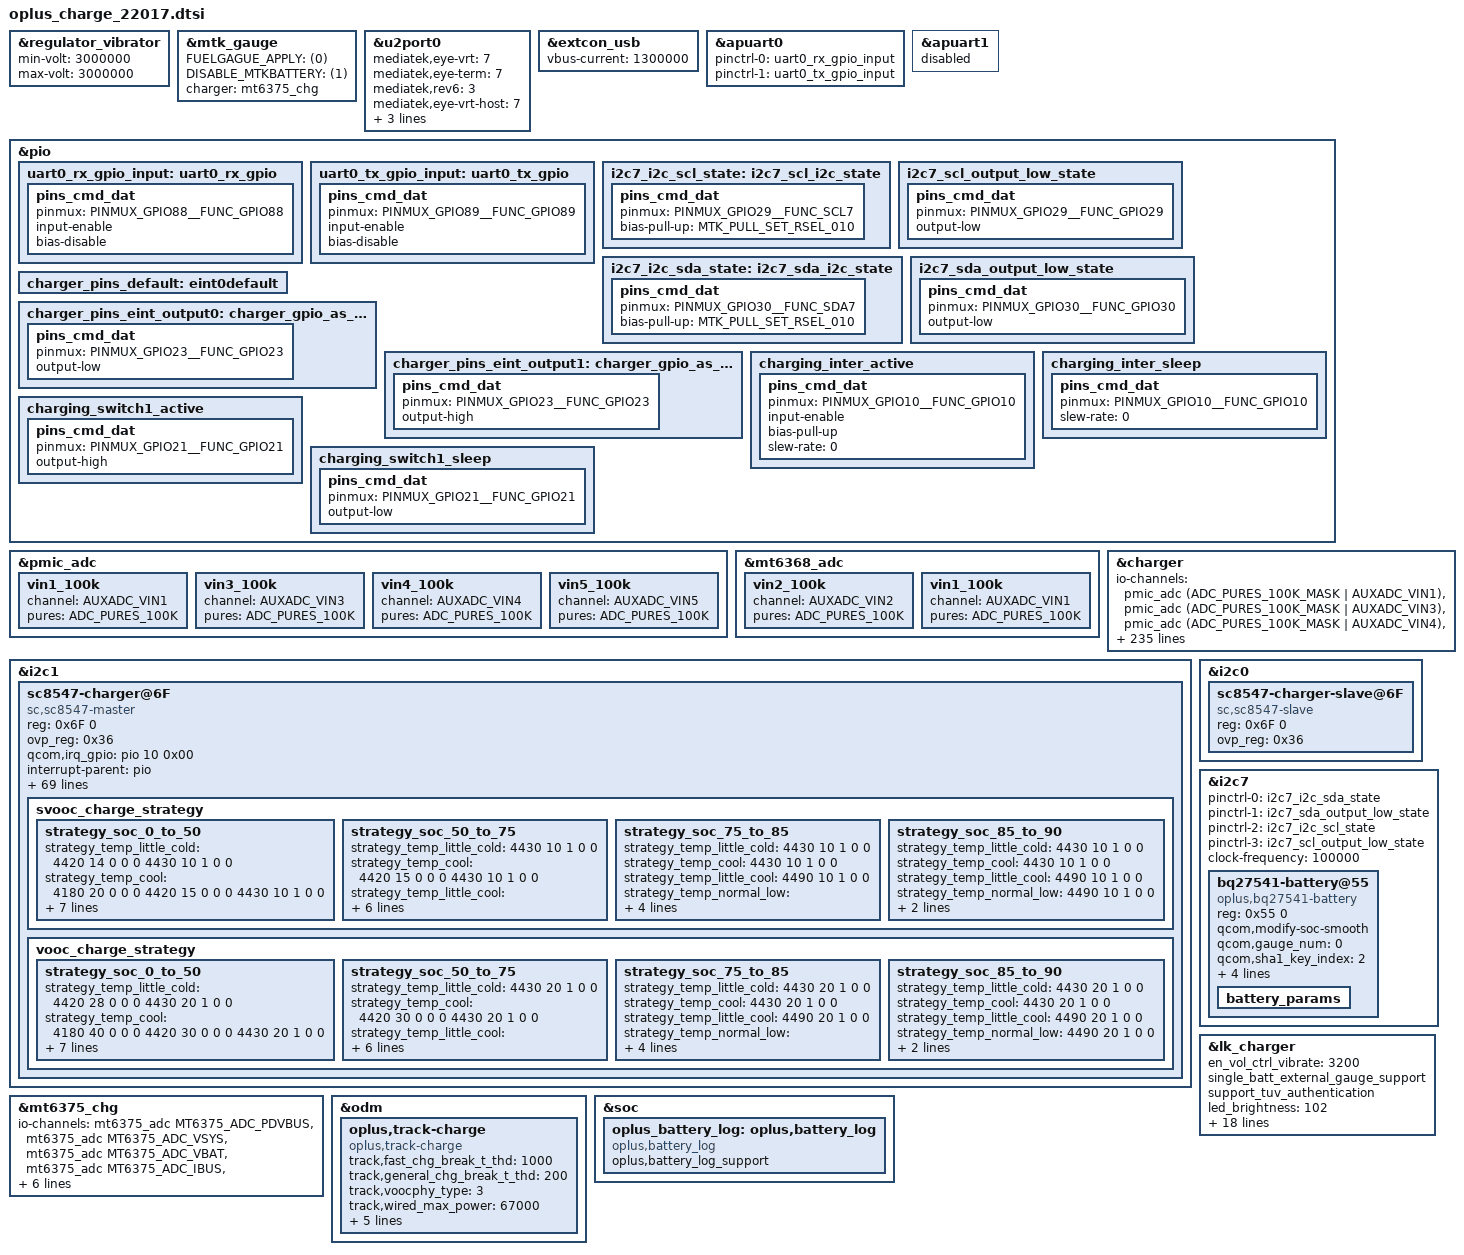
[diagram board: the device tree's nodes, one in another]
// SPDX-License-Identifier: GPL-2.0-only
/*
* Copyright (C) 2021-2020 Oplus. All rights reserved.
*/
#include <dt-bindings/iio/mt635x-auxadc.h>
#include <dt-bindings/pinctrl/mt6373-pinfunc.h>
#include <dt-bindings/pinctrl/mt65xx.h>
#include "oplus_chg.h"
#include <dt-bindings/iio/adc/mediatek,mt6375_adc.h>

&regulator_vibrator{
	min-volt = <3000000>;
	max-volt = <3000000>;
};

&mtk_gauge {
	FUELGAGUE_APPLY = <(0)>;
	DISABLE_MTKBATTERY = <(1)>;
	charger = <&mt6375_chg>;
};

&u2port0 {
	mediatek,eye-vrt = <7>;
	mediatek,eye-term = <7>;
	mediatek,rev6 = <3>;
	mediatek,eye-vrt-host = <7>;
	mediatek,eye-term-host = <7>;
	mediatek,rev6-host = <3>;
	mediatek,discth = <0xd>;
};

&extcon_usb {
	vbus-current = <1300000>;
};

&apuart0 {
	pinctrl-names = "uart0_rx_gpio", "uart0_tx_gpio";
	pinctrl-0 = <&uart0_rx_gpio_input>;
	pinctrl-1 = <&uart0_tx_gpio_input>;
	status = "okay";
};

&apuart1 {
	status = "disabled";
};

&pio {
	uart0_rx_gpio_input: uart0_rx_gpio {
		pins_cmd_dat {
			pinmux = <PINMUX_GPIO88__FUNC_GPIO88>;
			input-enable;
			bias-disable;
		};
	};

	uart0_tx_gpio_input: uart0_tx_gpio {
		pins_cmd_dat {
			pinmux = <PINMUX_GPIO89__FUNC_GPIO89>;
			input-enable;
			bias-disable;
		};
	};
};

&pmic_adc {
	vin1_100k {
		channel = <AUXADC_VIN1>;
		pures = <ADC_PURES_100K>;
	};
	vin3_100k {
		channel = <AUXADC_VIN3>;
		pures = <ADC_PURES_100K>;
	};
	vin4_100k {
		channel = <AUXADC_VIN4>;
		pures = <ADC_PURES_100K>;
	};
	vin5_100k {
		channel = <AUXADC_VIN5>;
		pures = <ADC_PURES_100K>;
	};
};

&mt6368_adc {
	vin2_100k {
		channel = <AUXADC_VIN2>;
		pures = <ADC_PURES_100K>;
	};
	vin1_100k {
		channel = <AUXADC_VIN1>;
		pures = <ADC_PURES_100K>;
	};
};

&charger {

	io-channels = <&pmic_adc (ADC_PURES_100K_MASK | AUXADC_VIN1)>,
			<&pmic_adc (ADC_PURES_100K_MASK | AUXADC_VIN3)>,
			<&pmic_adc (ADC_PURES_100K_MASK | AUXADC_VIN4)>,
			<&mt6368_adc AUXADC_VIN2>,
			<&mt6368_adc AUXADC_VIN1>,
			<&pmic_adc (ADC_PURES_100K_MASK | AUXADC_VIN5)>;
	io-channel-names = "auxadc2_ntc_sub_bat_tem",
			"usb_temp_v_l",
			"usb_temp_v_r",
			"auxadc5_batt_btb_temp",
			"auxadc6_usb_btb_temp",
			"auxadc5-chargeric_temp";

	pinctrl-names = "default",
			"charger_gpio_as_output_low",  /*Level 1 switch*/
			"charger_gpio_as_output_high";

	pinctrl-0 = <&charger_pins_default>;
	pinctrl-1 = <&charger_pins_eint_output0>;
	pinctrl-2 = <&charger_pins_eint_output1>;

	//for oplus chg framework:
	qcom,pd_input_current_charger_ma = <1500>;
	qcom,qc_input_current_charger_ma = <1500>;
	qcom,input_current_charger_ma = <2200>;
	qcom,input_current_usb_ma = <500>;
	qcom,input_current_cdp_ma = <1500>;
	qcom,input_current_camera_ma = <1200>;
	qcom,input_current_calling_ma = <1500>;

	qcom,led_warm_bat_decidegc = <350>;
	qcom,led_high_bat_decidegc = <370>;
	qcom,input_current_led_ma = <1200>;
	qcom,input_current_led_ma_high = <1200>;
	qcom,input_current_led_ma_warm = <1500>;
	qcom,input_current_led_ma_normal = <2000>;
	qcom,input_current_led_ma_forcmcc = <500>;
	qcom,input_current_led_ma_limit_high = <1200>;

	qcom,vooc_temp_bat_normal_decidegc = <350>;
	qcom,vooc_temp_bat_warm_decidegc = <370>;
	qcom,vooc_temp_bat_hot_decidegc = <440>;
	qcom,input_current_vooc_led_ma_high = <1200>;
	qcom,input_current_vooc_led_ma_warm = <1800>;
	qcom,input_current_vooc_led_ma_normal = <3600>;
	qcom,input_current_vooc_ma_normal = <3600>;
	qcom,input_current_vooc_ma_warm = <3200>;
	qcom,input_current_vooc_ma_high = <2200>;

	qcom,overtemp_bat_decidegc = <350>;
	qcom,iterm_disabled = <0>;
	//sw_full_count = <25>;
	qcom,iterm_ma = <255>;
	qcom,recharge-mv = <100>;

	qcom,batt_capacity_mah = <4500>; /*typical capacity*/
	//qcom,batt_capacity_mah = <4390>; /*rated capacity*/
	qcom,usb_high_than_bat_decidegc = <168>;

	qcom,removed_bat_decidegc = <390>;  /* < -39C */

	qcom,cold_bat_decidegc = <100>;  /* -10C ~ 0C */
	qcom,temp_cold_vfloat_mv = <4435>;
	qcom,temp_freeze_fastchg_current_ma_high = <1100>;
	qcom,temp_freeze_fastchg_current_ma_low = <1100>;
	qcom,temp_freeze_fastchg_current_ma = <1100>;
	qcom,temp_cold_fastchg_current_ma = <1100>;

	qcom,little_cold_bat_decidegc = <0>;    /* 0C ~ 5C */
	qcom,temp_little_cold_vfloat_mv = <4435>;
	qcom,temp_little_cold_fastchg_current_ma_high = <2200>;
	qcom,temp_little_cold_fastchg_current_ma_low = <2200>;
	qcom,temp_little_cold_fastchg_current_ma = <2200>;
	qcom,qc_temp_little_cold_fastchg_current_ma_high = <2594>;
	qcom,qc_temp_little_cold_fastchg_current_ma_low = <2700>;
	qcom,pd_temp_little_cold_fastchg_current_ma_high = <2594>;
	qcom,pd_temp_little_cold_fastchg_current_ma_low = <2700>;

	qcom,cool_bat_decidegc = <50>;  /* 5C ~ 12C */
	qcom,temp_cool_vfloat_mv = <4435>;
	qcom,temp_cool_fastchg_current_ma_high = <2200>;
	qcom,temp_cool_fastchg_current_ma_low = <2200>;
	qcom,qc_temp_cool_fastchg_current_ma_high = <2700>;
	qcom,qc_temp_cool_fastchg_current_ma_low = <2700>;
	qcom,pd_temp_cool_fastchg_current_ma_high = <2700>;
	qcom,pd_temp_cool_fastchg_current_ma_low = <2700>;

	qcom,little_cool_bat_decidegc = <120>;  /* 12C ~ 16C */
	qcom,temp_little_cool_vfloat_mv = <4435>;
	qcom,temp_little_cool_fastchg_current_ma = <2200>;
	qcom,pd_temp_little_cool_fastchg_current_ma = <2700>;
	qcom,qc_temp_little_cool_fastchg_current_ma = <2700>;

	qcom,normal_bat_decidegc = <160>;       /* 16C ~ 45C */
	qcom,temp_normal_vfloat_mv = <4435>;
	qcom,temp_normal_fastchg_current_ma = <2200>;
	qcom,pd_temp_normal_fastchg_current_ma = <2700>;
	qcom,qc_temp_normal_fastchg_current_ma = <2700>;

	qcom,warm_bat_decidegc = <450>;         /* 45C ~ 53C */ /*8pin Bat Vooc project need add 3 degree C*/
	qcom,temp_warm_vfloat_mv = <4130>;
	qcom,temp_warm_fastchg_current_ma = <1152>;
	qcom,pd_temp_warm_fastchg_current_ma = <1152>;
	qcom,qc_temp_warm_fastchg_current_ma = <1152>;
	qcom,temp_warm_fastchg_current_ma_led_on = <500>;

	qcom,hot_bat_decidegc = <530>;  /* > 53C */

	qcom,non_standard_vfloat_mv = <3980>;
	qcom,non_standard_fastchg_current_ma = <512>;

	qcom,short_c_bat_cv_mv = <4330>;
	qcom,short_c_bat_vfloat_mv = <3800>;
	qcom,short_c_bat_fastchg_current_ma = <512>;
	qcom,short_c_bat_vfloat_sw_limit = <3750>;

	qcom,cold_vfloat_sw_limit = <4385>;
	qcom,little_cold_vfloat_sw_limit = <4385>;
	qcom,cool_vfloat_sw_limit = <4385>;
	qcom,little_cool_vfloat_sw_limit = <4385>;
	qcom,normal_vfloat_sw_limit = <4385>;
	qcom,warm_vfloat_sw_limit = <4080>;
	qcom,non_standard_vfloat_sw_limit = <3930>;

	qcom,max_chg_time_sec = <64000>;
	qcom,charger_hv_thr = <10000>;
	qcom,charger_recv_thr = <9800>;
	qcom,charger_lv_thr = <3400>;
	qcom,vbatt_full_thr = <4435>;
	qcom,vbatt_hv_thr = <4600>;

	qcom,vfloat_step_mv = <16>;
	qcom,non_standard_vfloat_over_sw_limit = <3990>;
	qcom,cold_vfloat_over_sw_limit = <4445>;
	qcom,little_cold_vfloat_over_sw_limit = <4445>;
	qcom,cool_vfloat_over_sw_limit = <4445>;
	qcom,little_cool_vfloat_over_sw_limit = <4445>;
	qcom,normal_vfloat_over_sw_limit = <4445>;
	qcom,warm_vfloat_over_sw_limit = <4140>;

	qcom,usbtemp_batt_temp_low = <50>;
	qcom,usbtemp_batt_temp_high = <50>;
	qcom,usbtemp_ntc_temp_low = <57>;
	qcom,usbtemp_ntc_temp_high = <69>;
	qcom,usbtemp_temp_gap_low_with_batt_temp = <7>;
	qcom,usbtemp_temp_gap_high_with_batt_temp = <12>;
	qcom,usbtemp_temp_gap_low_without_batt_temp = <12>;
	qcom,usbtemp_temp_gap_high_without_batt_temp = <24>;
	qcom.usbtemp_rise_fast_temp_low = <3>;
	qcom.usbtemp_rise_fast_temp_high = <3>;
	qcom.usbtemp_rise_fast_temp_count_low = <30>;
	qcom.usbtemp_rise_fast_temp_count_high = <20>;

	qcom,usbtemp_cool_down_ntc_low = <54>;
	qcom,usbtemp_cool_down_ntc_high = <65>;
	qcom,usbtemp_cool_down_gap_low = <12>;
	qcom,usbtemp_cool_down_gap_high = <20>;
	qcom,usbtemp_cool_down_recover_ntc_low = <48>;
	qcom,usbtemp_cool_down_recover_ntc_high = <60>;
	qcom,usbtemp_cool_down_recover_gap_low = <6>;
	qcom,usbtemp_cool_down_recover_gap_high = <15>;

	qcom,vbatt_power_off = <3300>;
	qcom,vbatt_soc_1 = <3410>;
	qcom,vooc_project = <13>;
	qcom,vbatt_num = <1>;
	qcom,new_ui_warning_support;
	qcom,smart_charging_screenoff;
	qcom,smart_charge_version = <1>;

	qcom,normal_vterm_hw_inc = <18>;
	qcom,non_normal_vterm_hw_inc = <18>;
	qcom,usbtemp_batttemp_gap = <12>;

	qcom,ff1_normal_fastchg_ma = <1550>;
	qcom,ff1_warm_fastchg_ma = <1700>;	/* 35C ~ 40c */
	qcom,ff1_exit_step_ma = <100>;
	qcom,ff1_warm_exit_step_ma = <100>;
	qcom,ffc2_normal_fastchg_ma = <1550>;   /*12C~35c*/
	qcom,ffc2_warm_fastchg_ma = <1700>;	/* 35C ~ 40c */
	qcom,ffc2_temp_warm_decidegc = <350>;
	qcom,ffc2_temp_high_decidegc = <400>;
	qcom,ffc2_temp_low_decidegc = <120>;
	qcom,ffc2_exit_step_ma = <100>;
	qcom,ffc2_warm_exit_step_ma = <100>;

	qcom,ffc_normal_vfloat_sw_limit = <4485>;
	qcom,ffc2_normal_vfloat_sw_limit = <4485>;
	qcom,ffc_temp_normal_vfloat_mv = <4550>;
	qcom,ffc_normal_vfloat_over_sw_limit = <4550>;

	qcom,default_iterm_ma = <255>;
	qcom,default_temp_normal_fastchg_current_ma = <2200>;
	qcom,default_normal_vfloat_sw_limit = <4385>;
	qcom,default_temp_normal_vfloat_mv = <4435>;
	qcom,default_normal_vfloat_over_sw_limit = <4445>;

	qcom,default_temp_little_cool_fastchg_current_ma = <2200>;
	qcom,default_little_cool_vfloat_sw_limit = <4385>;
	qcom,default_temp_little_cool_vfloat_mv = <4435>;
	qcom,default_little_cool_vfloat_over_sw_limit = <4445>;

	oplus,poweroff_high_batt_temp = <720>;
	oplus,poweroff_emergency_batt_temp = <770>;
	oplus,usbtemp_batt_temp_over_hot = <60>;
	oplus,usbtemp_temp_gap_with_batt_temp_in_over_hot = <15>;

	//for PD9V or QC9V
	qcom,vbatt_pdqc_to_5v_thr = <4435>;
	qcom,vbatt_pdqc_to_9v_thr = <4435>;

	//for control:
	//qcom,suspend_after_full;
	//for smart charge begin
	qcom,smart_chg_bcc_support;
	//for smart charge end
	qcom,smart_chg_soh_support;
	qcom,check_batt_full_by_sw;
	qcom,chg_ctrl_by_lcd;
	qcom,chg_ctrl_by_camera;
	qcom,chg_ctrl_by_calling;
	qcom,sw_vfloat_over_protect_enable;
	qcom,usbtemp_dischg_by_pmic;
	qcom,support_usbtemp_protect_v2;
	qcom,support_abnormal_adapter;
	qcom,ffc_support;
	qcom,chargerid_vol_disable;
	qcom,support_ntc_01c_precision;
	qcom,voocphy_support = <3>;
	qcom,external_authenticate;
	qcom,chargerid_support;
	qcom,support_subboard_ntc;
	qcom,external_gauge;
	qcom,batt_num = <1>;
	qcom,vooc_show_ui_soc_decimal;
	qcom,ui_soc_decimal_speedmin = <20>;//2A
	qcom,ccdetect_by_wd0;
	oplus,boot_reset_adapter;
	//GPIO config:
	qcom,chargerid_switch-gpio = <&pio 23 0x00>;

	qcom,vooc-max-input-volt-support = <11000>;     //10V
	qcom,vooc-max-input-current-support = <3000>;   //6.5A

	oplus,switch2-ctrl-gpio = <&pio 21 0x00>;
	oplus,uart_tx-gpio = <&pio 89 0x00>;
	oplus,uart_rx-gpio = <&pio 88 0x00>;
};

/*#ifdef OPLUS_FEATURE_CHG_BASIC*/
&charger {
	//oplus,pps_ops = "cp-sc8571";
	qcom,pps_support_type = <0>;
	qcom,pps_warm_allow_vol = <4000>;
	qcom,pps_warm_allow_soc = <50>;
	qcom,pps_strategy_normal_current = <8000>;//6A
	qcom,pps_over_high_or_low_current = <8000>;
	qcom,pps_full_cool_sw_vbat = <4430>;
	qcom,pps_full_normal_sw_vbat = <4490>;
	qcom,pps_full_normal_hw_vbat = <4500>;
	qcom,pps_full_ffc_vbat = <4420>;
	qcom,pps_warm_full_voltage = <4130>;
	qcom,pps_full_cool_sw_vbat_30w = <4430>;
	qcom,pps_full_normal_sw_vbat_30w = <4430>;
	qcom,pps_full_normal_hw_vbat_30w = <4440>;
	oplus,pps_r_default = <120 10 10 15 15 15 15>;
	oplus,pps_rmos_mohm = <4>;
	oplus,pps_r_limit = <280 200 140 90 50>;
	oplus,pps_strategy_batt_high_temp = <425 430 435 400 415 420>;
	oplus,pps_strategy_high_current = <8000 8000 8000 8000 8000 8000>;
	oplus,pps_charge_strategy_soc = <0 15 35 55 75 85 95>;
	oplus,pps_charge_strategy_temp = <0 50 120 200 350 440 510>;
	oplus,pps_low_curr_full_strategy_temp = <120 200 350 440>;
};
/*endif OPLUS_FEATURE_CHG_BASIC*/

&i2c1 {
	status = "okay";
	sc8547-charger@6F{
		status = "okay";
		compatible = "sc,sc8547-master";
		reg = <0x6F 0>;
                ovp_reg = <0x36>; /* vbat_ovp:4.85V */

		qcom,irq_gpio = <&pio 10 0x00>;
		interrupt-parent = <&pio>;
		interrupts = <9 0>;

		pinctrl-names = "switch1_act_switch2_act", "switch1_sleep_switch2_sleep",
					"charging_inter_active", "charging_inter_sleep";
		pinctrl-0 = <&charging_switch1_active>; 
		pinctrl-1 = <&charging_switch1_sleep>;
		pinctrl-2 = <&charging_inter_active>;
		pinctrl-3 = <&charging_inter_sleep>;

		qcom,external_gauge_support;
		qcom,charging_switch1-gpio = <&pio 21 0x00>;

		qcom,voocphy_dual_cp_support;
		qcom,copycat_vooc_support;
		qcom,slave_cp_enable_thr = <1400>;		//2000-100mA
		qcom,slave_cp_disable_thr_high = <1100>;	//1500+100mA
		qcom,voocphy_current_default = <61>;

		qcom,svooc_cool_down_current_limit = <122 20 20 24 30 34 40 44 50 54 60 64 70 74>;
		qcom,vooc_cool_down_current_limit = <61 20 20 24 30 34 40 44 50 54 60 64 70 74>;

		qcom,vooc_multistep_initial_batt_temp = <1000>;
		qcom,vooc_little_cool_temp = <160>;
		qcom,vooc_cool_temp = <120>;
		qcom,vooc_little_cold_temp = <50>;
		qcom,vooc_normal_low_temp = <350>;
		qcom,vooc_strategy_normal_current = <122>;
		qcom,vooc_normal_to_little_cool_current = <100>;
		qcom,vooc_batt_over_high_temp = <510>;
		qcom,vooc-low-temp = <0>;

		qcom,vooc-high-temp = <500>;
		qcom,vooc-low-soc = <0>;
		qcom,vooc-high-soc = <90>;
		qcom,vooc-normal-high-temp = <430>;
		qcom,vooc-warm-allow-vol = <4000>;
		qcom,vooc-warm-allow-soc = <50>;

		qcom,vooc_strategy1_batt_high_temp0 = <385>;
		qcom,vooc_strategy1_batt_high_temp1 = <395>;
		qcom,vooc_strategy1_batt_high_temp2 = <420>;
		qcom,vooc_strategy1_batt_low_temp2 = <410>;
		qcom,vooc_strategy1_batt_low_temp1 = <385>;
		qcom,vooc_strategy1_batt_low_temp0 = <375>;

		qcom,vooc_strategy1_high_current0 = <80>;
		qcom,vooc_strategy1_high_current1 = <60>;
		qcom,vooc_strategy1_high_current2 = <40>;
		qcom,vooc_strategy1_low_current2 = <60>;
		qcom,vooc_strategy1_low_current1 = <80>;
		qcom,vooc_strategy1_low_current0 = <122>;

		qcom,voocphy_freq_mincore = <968000>;
		qcom,voocphy_freq_midcore = <1418000>;
		qcom,voocphy_freq_maxcore = <1418000>;
		qcom,voocphy_current_change_timeout = <100>;

		qcom,voocphy_ibat_over_current = <13500>;
		qcom,voocphy_svooc_cp_max_ibus = <3500>;
		qcom,voocphy_vooc_cp_max_ibus = <3500>;
		qcom,voocphy_cp_max_ibus = <3500>;

		qcom,abnormal_adapter_current = <122 50 50 50 40 40 30 30 20 20>;

		qcom,vooc_little_cold_full_voltage = <4430>;
		qcom,vooc_cool_full_voltage = <4430>;
		qcom,vooc_warm_full_voltage = <4130>;
		qcom,vooc_1time_full_voltage = <4490>;
		qcom,vooc_ntime_full_voltage = <4490>;
		qcom,low_curr_full_t1 = <120>;
		qcom,low_curr_full_t2 = <350>;
		qcom,low_curr_full_t3 = <430>;
		qcom,range1_low_curr_full = <1500 4490
						1400 4485
						1300 4470
						1200 4460
						1100 4450>;
		qcom,range2_low_curr_full = <1600 4490
						1400 4485
						1300 4470
						1200 4460
						1100 4450>;

		svooc_batt_sys_curve = <0 1 0 1 0 0 0	// 4000mA
					1 1 1 1 0 0 0	// 4604mV
					0 0 1 1 0 1 0	// 2600mA
					1 1 1 1 0 0 0	// 4604mV
					0 0 0 1 0 1 1	// 1100mA
					1 1 1 1 0 0 0>;	// 4604mV

		vooc_batt_sys_curve =  <0 1 0 1 0 0 0	// 4000mA
					1 1 1 1 0 0 0	// 4604mV
					0 0 1 1 0 1 0	// 2600mA
					1 1 1 1 0 0 0	// 4604mV
					0 0 0 1 0 1 1	// 1100mA
					1 1 1 1 0 0 0>;	// 4604mV

		svooc_charge_strategy {
			strategy_soc_0_to_50 {
				strategy_temp_little_cold =	<4420 14 0 0 0
								 4430 10 1 0 0>;
				strategy_temp_cool =	<4180 20 0 0 0
								 4420 15 0 0 0
								 4430 10 1 0 0>;
				strategy_temp_little_cool =	<4180 40 0 0 0
								 4350 30 0 0 0
								 4350 25 0 0 0
								 4480 20 0 0 0
								 4480 15 0 0 0
								 4490 10 1 0 0>;
				strategy_temp_normal_low =	<4200 61 0 60 0 //min*60*1000/500
								 4200 50 0 600 0 //min*60*1000/500
								 4350 40 0 0 0 //min*60*1000/500
								 4450 30 0 0 0
								 4450 25 0 0 0
								 4480 20 0 0 0
								 4480 15 0 0 0
								 4490 10 1 0 0>;
				strategy_temp_normal_high =	<4200 50 0 600 0 //min*60*1000/500
								 4350 40 0 1200 0 //min*60*1000/500
								 4450 30 0 0 0
								 4450 25 0 0 0
								 4480 20 0 0 0
								 4480 15 0 0 0
								 4490 10 1 0 0>;
				strategy_temp_warm = <4130 10 1 0 0>;
			};

			strategy_soc_50_to_75 {
				strategy_temp_little_cold =	<4430 10 1 0 0>;
				strategy_temp_cool =	<4420 15 0 0 0
								 4430 10 1 0 0>;
				strategy_temp_little_cool =	<4480 20 0 0 0
								 4480 15 0 0 0
								 4490 10 1 0 0>;
				strategy_temp_normal_low =	<4450 25 0 0 0
								 4480 20 0 0 0
								 4480 15 0 0 0
								 4490 10 1 0 0>;
				strategy_temp_normal_high =	<4450 25 0 0 0
								 4480 20 0 0 0
								 4480 15 0 0 0
								 4490 10 1 0 0>;
				strategy_temp_warm = <4130 10 1 0 0>;
			};

			strategy_soc_75_to_85 {
				strategy_temp_little_cold =	<4430 10 1 0 0>;
				strategy_temp_cool =	<4430 10 1 0 0>;
				strategy_temp_little_cool =	<4490 10 1 0 0>;
				strategy_temp_normal_low =	<4480 15 0 0 0
								 4490 10 1 0 0>;
				strategy_temp_normal_high =	<4480 15 0 0 0
								 4490 10 1 0 0>;
				strategy_temp_warm = <4130 10 1 0 0>;
			};

			strategy_soc_85_to_90 {
				strategy_temp_little_cold =	<4430 10 1 0 0>;
				strategy_temp_cool =	<4430 10 1 0 0>;
				strategy_temp_little_cool =	<4490 10 1 0 0>;
				strategy_temp_normal_low =	<4490 10 1 0 0>;
				strategy_temp_normal_high =	<4490 10 1 0 0>;
				strategy_temp_warm = <4130 10 1 0 0>;
			};
		};

		vooc_charge_strategy {
			strategy_soc_0_to_50 {
				strategy_temp_little_cold =	<4420 28 0 0 0
								 4430 20 1 0 0>;
				strategy_temp_cool =	<4180 40 0 0 0
								 4420 30 0 0 0
								 4430 20 1 0 0>;
				strategy_temp_little_cool =	<4350 59 0 1800 0
								 4350 50 0 0 0
								 4480 40 0 0 0
								 4480 30 0 0 0
								 4490 20 1 0 0>;
				strategy_temp_normal_low =	<4450 59 0 1800 0
								 4450 50 0 0 0
								 4480 40 0 0 0
								 4480 30 0 0 0
								 4490 20 1 0 0>;
				strategy_temp_normal_high =	<4450 59 0 1800 0
								 4450 50 0 0 0
								 4480 40 0 0 0
								 4480 30 0 0 0
								 4490 20 1 0 0>;
				strategy_temp_warm = <4130 20 1 0 0>;
			};

			strategy_soc_50_to_75 {
				strategy_temp_little_cold =	<4430 20 1 0 0>;
				strategy_temp_cool =	<4420 30 0 0 0
								 4430 20 1 0 0>;
				strategy_temp_little_cool =	<4475 40 0 0 0
								 4480 30 0 0 0
								 4490 20 1 0 0>;
				strategy_temp_normal_low =	<4450 50 0 0 0
								 4480 40 0 0 0
								 4480 30 0 0 0
								 4490 20 1 0 0>;
				strategy_temp_normal_high =	<4450 50 0 0 0
								 4480 40 0 0 0
								 4480 30 0 0 0
								 4490 20 1 0 0>;
				strategy_temp_warm = <4130 20 1 0 0>;
			};

			strategy_soc_75_to_85 {
				strategy_temp_little_cold =	<4430 20 1 0 0>;
				strategy_temp_cool =	<4430 20 1 0 0>;
				strategy_temp_little_cool =	<4490 20 1 0 0>;
				strategy_temp_normal_low =	<4480 30 0 0 0
								 4490 20 1 0 0>;
				strategy_temp_normal_high =	<4480 30 0 0 0
								 4490 20 1 0 0>;
				strategy_temp_warm = <4130 20 1 0 0>;
			};

			strategy_soc_85_to_90 {
				strategy_temp_little_cold =	<4430 20 1 0 0>;
				strategy_temp_cool =	<4430 20 1 0 0>;
				strategy_temp_little_cool =	<4490 20 1 0 0>;
				strategy_temp_normal_low =	<4490 20 1 0 0>;
				strategy_temp_normal_high =	<4490 20 1 0 0>;
				strategy_temp_warm = <4130 20 1 0 0>;
			};
		};

	};
};

&i2c0 {
	status = "okay";
	sc8547-charger-slave@6F{
		status = "okay";
		compatible = "sc,sc8547-slave";
		reg = <0x6F 0>;
                ovp_reg = <0x36>; /* vbat_ovp:4.85V */
	};
};

&i2c7 {
	pinctrl-names = "i2c-state", "output-low-state", "i2c-state-1", "output-low-state-1";
	pinctrl-0 = <&i2c7_i2c_sda_state>;
	pinctrl-1 = <&i2c7_sda_output_low_state>;
	pinctrl-2 = <&i2c7_i2c_scl_state>;
	pinctrl-3 = <&i2c7_scl_output_low_state>;
};

&pio {
	i2c7_i2c_scl_state: i2c7_scl_i2c_state {
		pins_cmd_dat {
			pinmux = <PINMUX_GPIO29__FUNC_SCL7>;
			bias-pull-up = <MTK_PULL_SET_RSEL_010>;
		};
	};
	i2c7_scl_output_low_state: i2c7_scl_output_low_state {
		pins_cmd_dat {
			pinmux = <PINMUX_GPIO29__FUNC_GPIO29>;
			output-low;
		};
	};

	i2c7_i2c_sda_state: i2c7_sda_i2c_state {
		pins_cmd_dat {
			pinmux = <PINMUX_GPIO30__FUNC_SDA7>;
			bias-pull-up = <MTK_PULL_SET_RSEL_010>;
		};
	};
	i2c7_sda_output_low_state: i2c7_sda_output_low_state {
		pins_cmd_dat {
			pinmux = <PINMUX_GPIO30__FUNC_GPIO30>;
			output-low;
		};
	};
};

&i2c7 {
	status = "okay";
	clock-frequency = <100000>;

	bq27541-battery@55 {
		status = "okay";
		compatible = "oplus,bq27541-battery";
		reg = <0x55 0>;
		qcom,modify-soc-smooth;
		qcom,gauge_num = <0>;
		qcom,sha1_key_index = <2>;

		zy,gauge-fix-cadc;
		zy,gauge-cal-board;
		zy,gauge-check-model;
		zy,gauge-check-por;
		battery_params {
			#include "oplus_charge_22017_blp973_afi.dtsi"
		};
	};
};

&pio {
	charger_pins_default: eint0default {
	};
	charger_pins_eint_output0: charger_gpio_as_output_low {
		pins_cmd_dat {
			pinmux = <PINMUX_GPIO23__FUNC_GPIO23>;
			output-low;
		};
	};

	charger_pins_eint_output1: charger_gpio_as_output_high {
		pins_cmd_dat {
			pinmux = <PINMUX_GPIO23__FUNC_GPIO23>;
			output-high;
		};
	};

	charging_inter_active: charging_inter_active {
		pins_cmd_dat {
			pinmux = <PINMUX_GPIO10__FUNC_GPIO10>;
			input-enable;
			bias-pull-up;
			slew-rate = <0>;
		};
	};
	charging_inter_sleep: charging_inter_sleep {
		pins_cmd_dat {
			pinmux = <PINMUX_GPIO10__FUNC_GPIO10>;
			slew-rate = <0>;
		};
	};

	charging_switch1_active: charging_switch1_active {
		pins_cmd_dat {
			pinmux = <PINMUX_GPIO21__FUNC_GPIO21>;
			output-high;
		};
	};

	charging_switch1_sleep: charging_switch1_sleep {
		pins_cmd_dat {
			pinmux = <PINMUX_GPIO21__FUNC_GPIO21>;
			output-low;
		};
	};
};

&mt6375_chg {
	io-channels = <&mt6375_adc MT6375_ADC_PDVBUS>,
		      <&mt6375_adc MT6375_ADC_VSYS>,
		      <&mt6375_adc MT6375_ADC_VBAT>,
		      <&mt6375_adc MT6375_ADC_IBUS>,
		      <&mt6375_adc MT6375_ADC_IBAT>,
		      <&mt6375_adc MT6375_ADC_TEMPJC>,
		      <&mt6375_adc MT6375_ADC_USBDP>,
		      <&mt6375_adc MT6375_ADC_USBDM>;

	ircmp_r = <0>;
	ircmp_v = <32>;
};

&lk_charger {
	en_vol_ctrl_vibrate = <3200>;
	single_batt_external_gauge_support;
	support_tuv_authentication;
	led_brightness = <102>;
	support_external_gauge_battery_encryption;
	charger_no_wiress;
	sub_board_temp_support;
	support_sdp_screenoff;

	high-temp-scheme;
	over_high_temp_thr = <60>;

	support_battery_type = <2>;  /* BATTERY_4P45V_SINGLE */
	max_charger_voltage = <15000000>;
	boot_battery_voltage = <3400000>;
	usb_charger_current = <500000>;
	ac_charger_current = <2050000>;
	ac_charger_input_current = <1500000>;
	non_std_ac_charger_current = <750000>;
	charging_host_charger_current = <1500000>;
	ta_ac_charger_current = <1500000>;
	pd_charger_current = <500000>;
	is_support_mt6375;
	support_zy0602_gauge;
};

&odm {
	oplus,track-charge {
		compatible = "oplus,track-charge";
		track,fast_chg_break_t_thd = <1000>;
		track,general_chg_break_t_thd = <200>;
		track,voocphy_type = <3>;
		track,wired_max_power = <67000>;
		track,wired_fast_chg_scheme = <2>;
		track,gauge_status_ctrl;
		track,nominal_qmax1 = <4535>;
		track,nominal_fcc1 = <4440>;
		track,external_gauge_num = <1>;
	};
};

&soc {
	oplus_battery_log: oplus,battery_log {
		compatible = "oplus,battery_log";
		oplus,battery_log_support;
	};
};
